# STM32H755ZIT7@M7 register map
File version: 1.0
Registers are 32-bit, access not given, reset 0x0 unless marked. A register's access mark holds for its fields unless they carry their own. Offsets are from the block's base; [hi:lo] are bit positions; {n}, {i} and the like mark numbered series; 'fields as' and 'values as' point back to an identical list.

## FDCAN_CCU
Base 0x4000A800
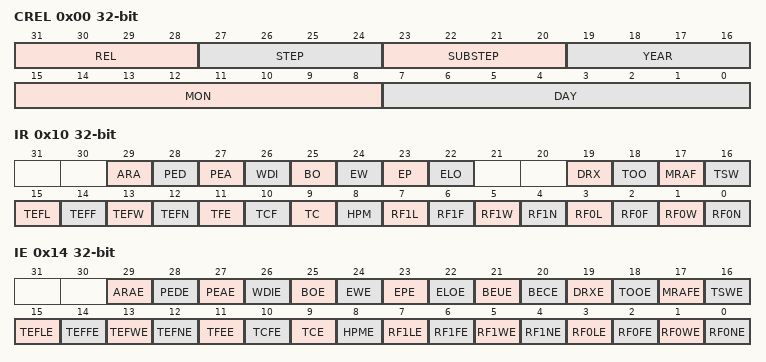
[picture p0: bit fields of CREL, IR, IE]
0x00 CREL
  [31:28] REL, [27:24] STEP, [23:20] SUBSTEP, [19:16] YEAR, [15:8] MON, [7:0] DAY
0x04 CCFG
0x08 CSTAT
0x0C CWD
0x10 IR
  [29] ARA, [28] PED, [27] PEA, [26] WDI, [25] BO, [24] EW, [23] EP, [22] ELO, [19] DRX, [18] TOO, [17] MRAF, [16] TSW, [15] TEFL, [14] TEFF, [13] TEFW, [12] TEFN, [11] TFE, [10] TCF, [9] TC, [8] HPM, [7] RF1L, [6] RF1F, [5] RF1W, [4] RF1N, [3] RF0L, [2] RF0F, [1] RF0W, [0] RF0N
0x14 IE
  [29] ARAE, [28] PEDE, [27] PEAE, [26] WDIE, [25] BOE, [24] EWE, [23] EPE, [22] ELOE, [21] BEUE, [20] BECE, [19] DRXE, [18] TOOE, [17] MRAFE, [16] TSWE, [15] TEFLE, [14] TEFFE, [13] TEFWE, [12] TEFNE, [11] TFEE, [10] TCFE, [9] TCE, [8] HPME, [7] RF1LE, [6] RF1FE, [5] RF1WE, [4] RF1NE, [3] RF0LE, [2] RF0FE, [1] RF0WE, [0] RF0NE

## SAI1
Base 0x40015800
Same registers: SAI2 0x40015C00, SAI3 0x40016000, SAI4 0x58005400
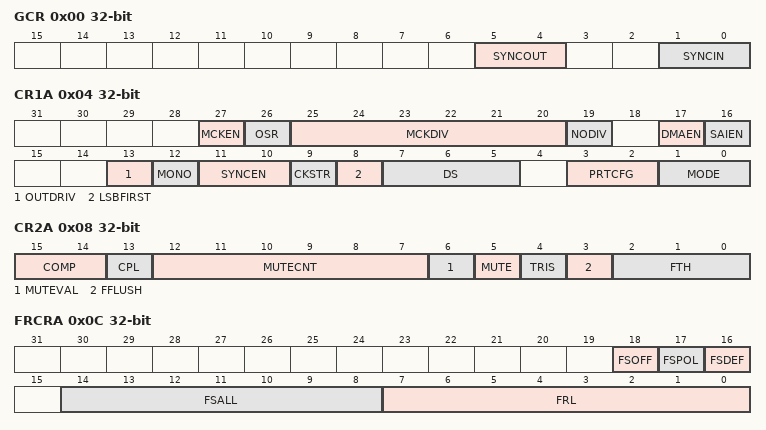
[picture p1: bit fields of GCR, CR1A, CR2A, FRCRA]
0x00 GCR
  [5:4] SYNCOUT, [1:0] SYNCIN
0x04 CR1A
  [27] MCKEN, [26] OSR, [25:20] MCKDIV, [19] NODIV, [17] DMAEN, [16] SAIEN, [13] OUTDRIV, [12] MONO, [11:10] SYNCEN, [9] CKSTR, [8] LSBFIRST, [7:5] DS, [3:2] PRTCFG, [1:0] MODE
0x08 CR2A
  [15:14] COMP, [13] CPL, [12:7] MUTECNT, [6] MUTEVAL, [5] MUTE, [4] TRIS, [3] FFLUSH, [2:0] FTH
0x0C FRCRA
  [18] FSOFF, [17] FSPOL, [16] FSDEF, [14:8] FSALL, [7:0] FRL
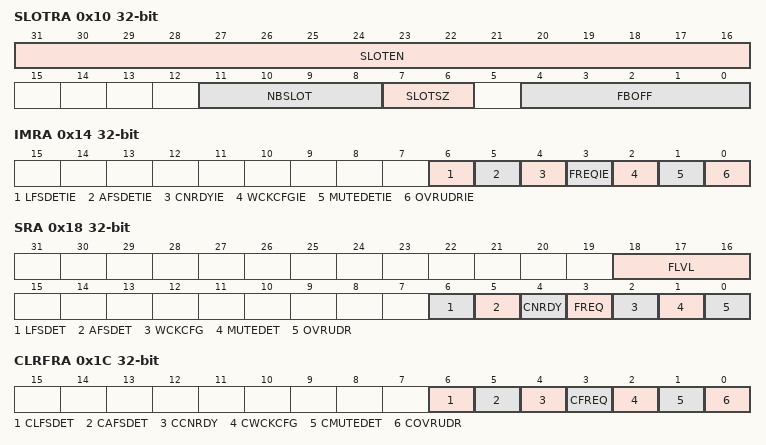
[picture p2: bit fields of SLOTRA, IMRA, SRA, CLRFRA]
0x10 SLOTRA
  [31:16] SLOTEN, [11:8] NBSLOT, [7:6] SLOTSZ, [4:0] FBOFF
0x14 IMRA
  [6] LFSDETIE, [5] AFSDETIE, [4] CNRDYIE, [3] FREQIE, [2] WCKCFGIE, [1] MUTEDETIE, [0] OVRUDRIE
0x18 SRA
  [18:16] FLVL, [6] LFSDET, [5] AFSDET, [4] CNRDY, [3] FREQ, [2] WCKCFG, [1] MUTEDET, [0] OVRUDR
0x1C CLRFRA
  [6] CLFSDET, [5] CAFSDET, [4] CCNRDY, [3] CFREQ, [2] CWCKCFG, [1] CMUTEDET, [0] COVRUDR
0x20 DRA
  [31:0] DATA
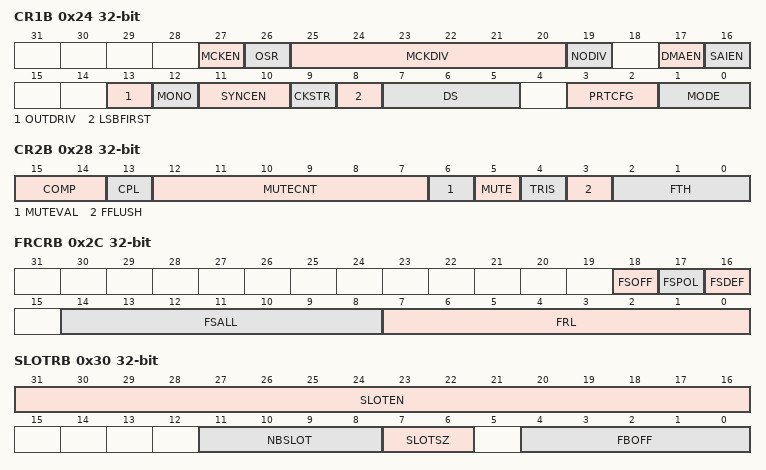
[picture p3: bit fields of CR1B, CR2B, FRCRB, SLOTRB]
0x24 CR1B
  fields as CR1A
0x28 CR2B
  fields as CR2A
0x2C FRCRB
  [18] FSOFF, [17] FSPOL, [16] FSDEF, [14:8] FSALL, [7:0] FRL
0x30 SLOTRB
  [31:16] SLOTEN, [11:8] NBSLOT, [7:6] SLOTSZ, [4:0] FBOFF
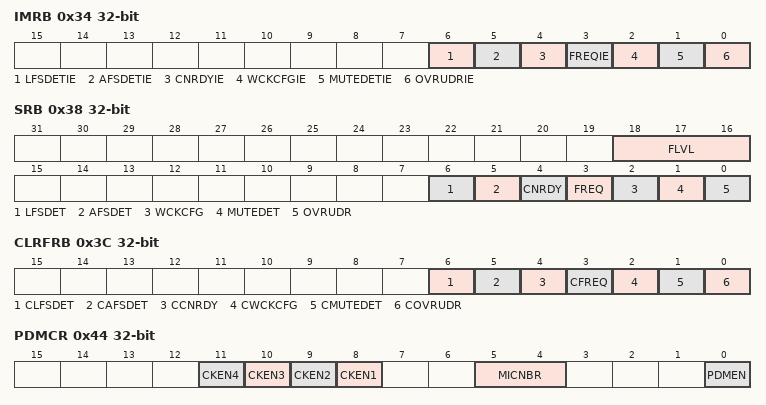
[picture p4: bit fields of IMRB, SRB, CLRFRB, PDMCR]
0x34 IMRB
  fields as IMRA
0x38 SRB
  fields as SRA
0x3C CLRFRB
  fields as CLRFRA
0x40 DRB
  [31:0] DATA
0x44 PDMCR
  [n+7] CKEN{n} (n=1..4), [5:4] MICNBR, [0] PDMEN
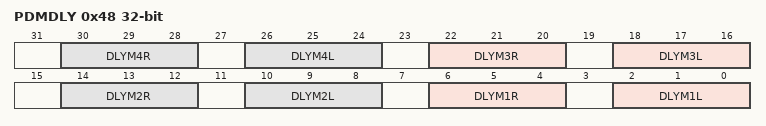
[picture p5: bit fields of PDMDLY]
0x48 PDMDLY
  [8n-2:8n-4] DLYM{n}R (n=1..4), [8n-6:8n-8] DLYM{n}L (n=1..4)

## DFSDM1
Base 0x40017000
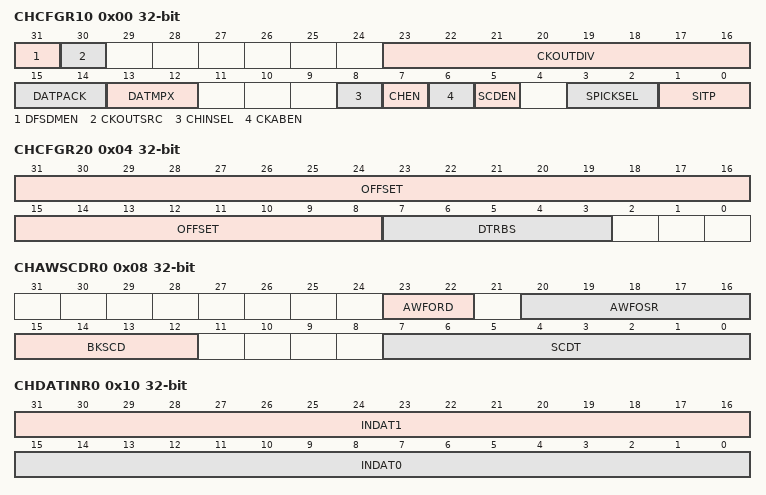
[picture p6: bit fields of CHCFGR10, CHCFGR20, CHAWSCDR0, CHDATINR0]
0x00 CHCFGR10
  [31] DFSDMEN, [30] CKOUTSRC, [23:16] CKOUTDIV, [15:14] DATPACK, [13:12] DATMPX, [8] CHINSEL, [7] CHEN, [6] CKABEN, [5] SCDEN, [3:2] SPICKSEL, [1:0] SITP
0x04 CHCFGR20
  [31:8] OFFSET, [7:3] DTRBS
0x08 CHAWSCDR0
  [23:22] AWFORD, [20:16] AWFOSR, [15:12] BKSCD, [7:0] SCDT
0x0C CHWDATAR0
0x10 CHDATINR0
  [31:16] INDAT1, [15:0] INDAT0
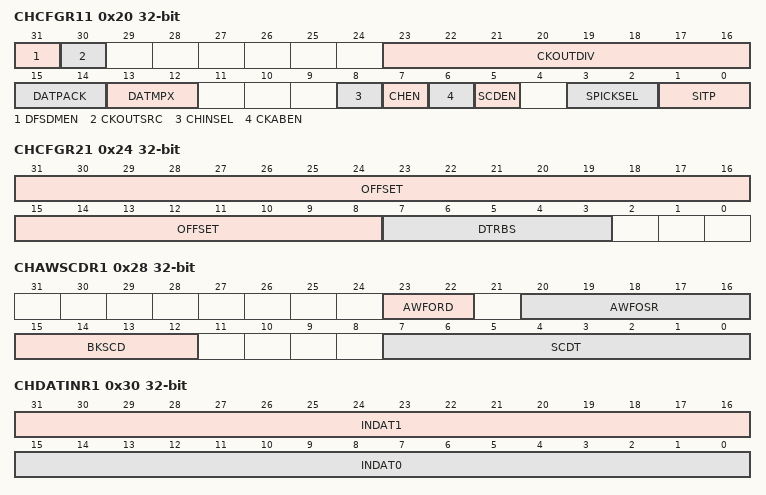
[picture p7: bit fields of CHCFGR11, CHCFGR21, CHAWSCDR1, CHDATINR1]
0x20 CHCFGR11
  fields as CHCFGR10
0x24 CHCFGR21
  [31:8] OFFSET, [7:3] DTRBS
0x28 CHAWSCDR1
  [23:22] AWFORD, [20:16] AWFOSR, [15:12] BKSCD, [7:0] SCDT
0x2C CHWDATAR1
0x30 CHDATINR1
  [31:16] INDAT1, [15:0] INDAT0
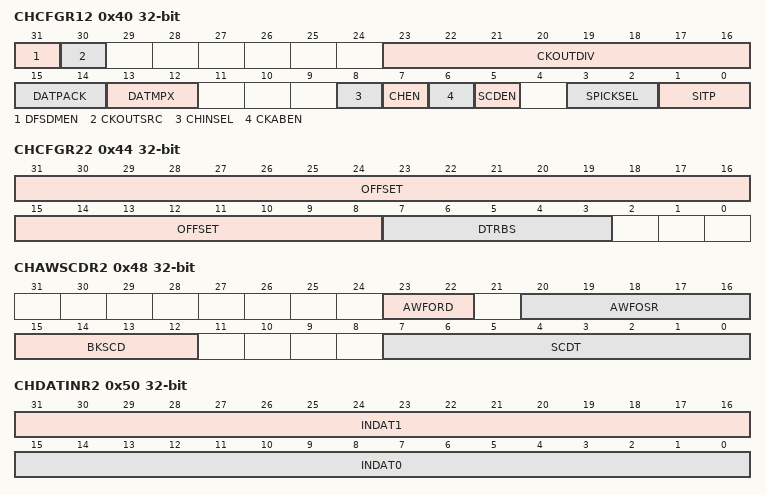
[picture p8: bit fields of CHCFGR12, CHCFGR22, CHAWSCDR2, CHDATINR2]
0x40 CHCFGR12
  fields as CHCFGR10
0x44 CHCFGR22
  [31:8] OFFSET, [7:3] DTRBS
0x48 CHAWSCDR2
  [23:22] AWFORD, [20:16] AWFOSR, [15:12] BKSCD, [7:0] SCDT
0x4C CHWDATAR2
0x50 CHDATINR2
  [31:16] INDAT1, [15:0] INDAT0
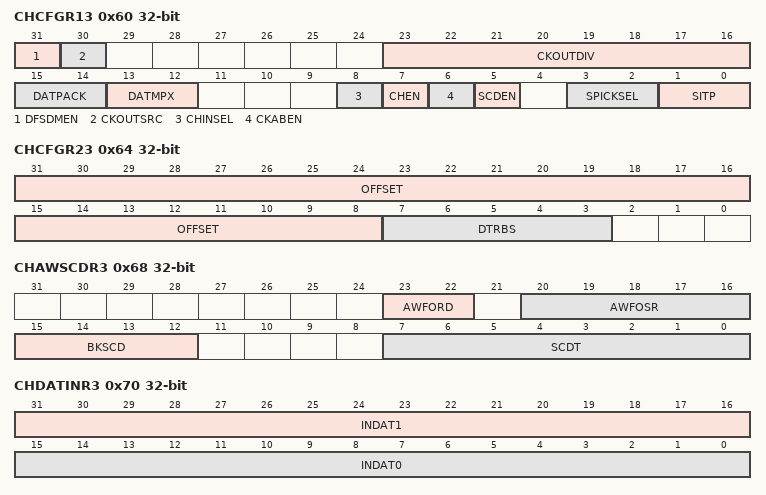
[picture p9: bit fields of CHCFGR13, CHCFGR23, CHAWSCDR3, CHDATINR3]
0x60 CHCFGR13
  fields as CHCFGR10
0x64 CHCFGR23
  [31:8] OFFSET, [7:3] DTRBS
0x68 CHAWSCDR3
  [23:22] AWFORD, [20:16] AWFOSR, [15:12] BKSCD, [7:0] SCDT
0x6C CHWDATAR3
0x70 CHDATINR3
  [31:16] INDAT1, [15:0] INDAT0
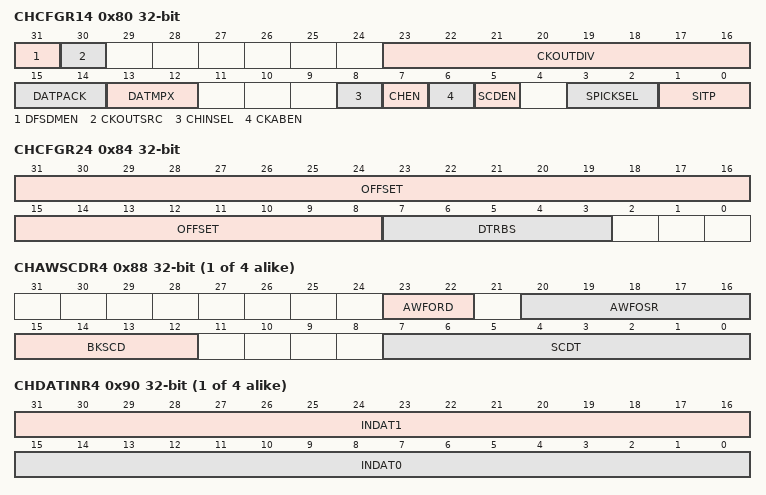
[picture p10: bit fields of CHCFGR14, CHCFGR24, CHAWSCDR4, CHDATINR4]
0x80 CHCFGR14
  fields as CHCFGR10
0x84 CHCFGR24
  [31:8] OFFSET, [7:3] DTRBS
{0x8+0x20*i} CHAWSCDR{i} (i=4..7)
  [23:22] AWFORD, [20:16] AWFOSR, [15:12] BKSCD, [7:0] SCDT
{0xC+0x20*i} CHWDATAR{i} (i=4..7)
{0x10+0x20*i} CHDATINR{i} (i=4..7)
  [31:16] INDAT1, [15:0] INDAT0
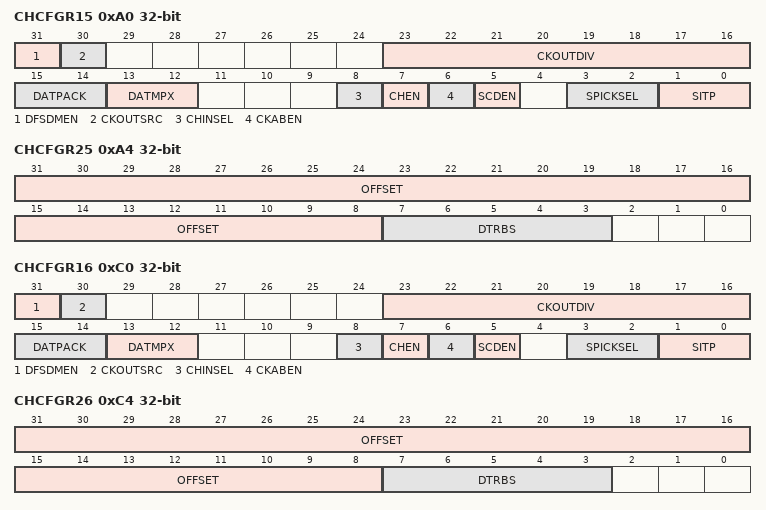
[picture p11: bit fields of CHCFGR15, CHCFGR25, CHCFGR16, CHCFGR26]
0xA0 CHCFGR15
  fields as CHCFGR10
0xA4 CHCFGR25
  [31:8] OFFSET, [7:3] DTRBS
0xC0 CHCFGR16
  fields as CHCFGR10
0xC4 CHCFGR26
  [31:8] OFFSET, [7:3] DTRBS
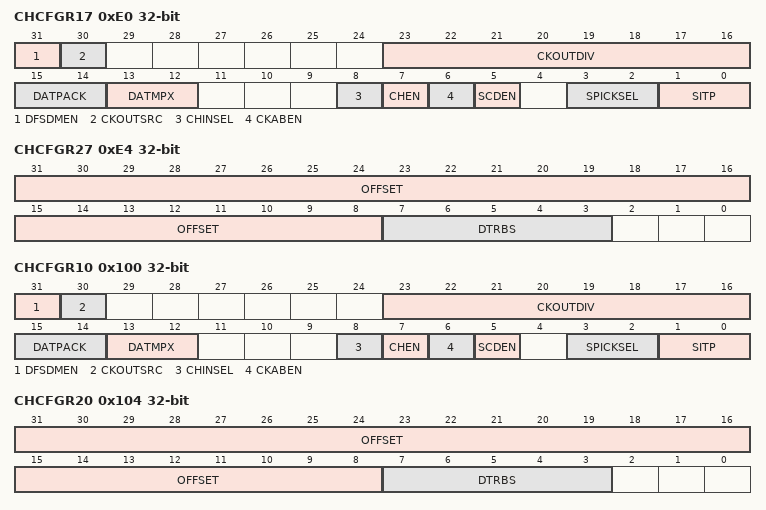
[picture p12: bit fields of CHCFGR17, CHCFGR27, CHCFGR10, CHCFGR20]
0xE0 CHCFGR17
  fields as CHCFGR10
0xE4 CHCFGR27
  [31:8] OFFSET, [7:3] DTRBS
0x100 CHCFGR10
  fields as CHCFGR10
0x104 CHCFGR20
  [31:8] OFFSET, [7:3] DTRBS
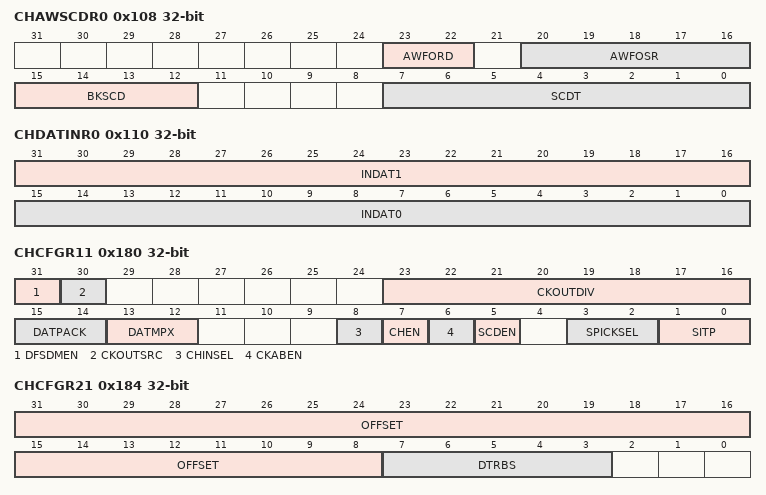
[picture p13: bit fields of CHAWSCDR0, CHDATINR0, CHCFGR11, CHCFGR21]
0x108 CHAWSCDR0
  [23:22] AWFORD, [20:16] AWFOSR, [15:12] BKSCD, [7:0] SCDT
0x10C CHWDATAR0
0x110 CHDATINR0
  [31:16] INDAT1, [15:0] INDAT0
0x180 CHCFGR11
  fields as CHCFGR10
0x184 CHCFGR21
  [31:8] OFFSET, [7:3] DTRBS
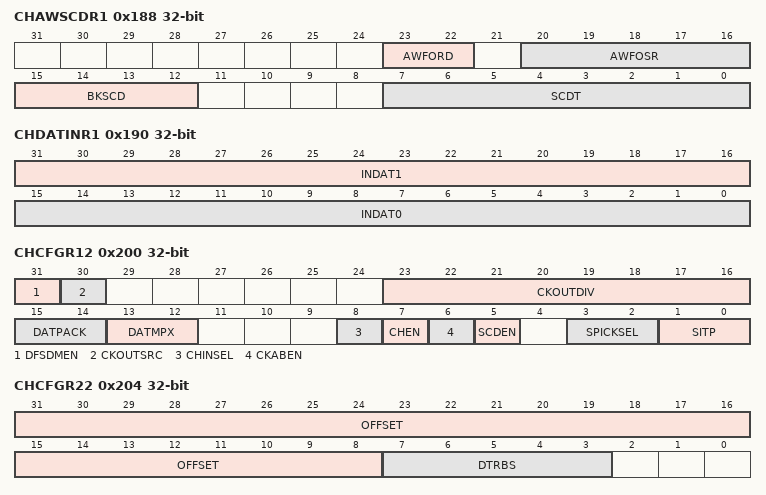
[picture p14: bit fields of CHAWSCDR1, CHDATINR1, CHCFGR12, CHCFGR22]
0x188 CHAWSCDR1
  [23:22] AWFORD, [20:16] AWFOSR, [15:12] BKSCD, [7:0] SCDT
0x18C CHWDATAR1
0x190 CHDATINR1
  [31:16] INDAT1, [15:0] INDAT0
0x200 CHCFGR12
  fields as CHCFGR10
0x204 CHCFGR22
  [31:8] OFFSET, [7:3] DTRBS
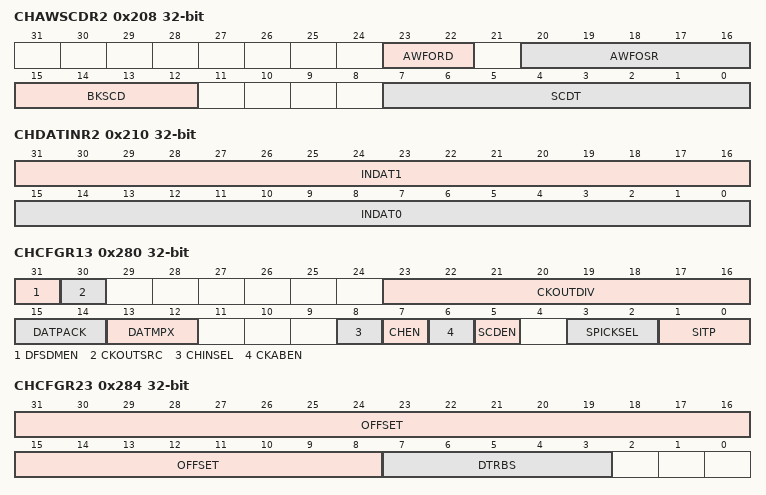
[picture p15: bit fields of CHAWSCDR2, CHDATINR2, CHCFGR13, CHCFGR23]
0x208 CHAWSCDR2
  [23:22] AWFORD, [20:16] AWFOSR, [15:12] BKSCD, [7:0] SCDT
0x20C CHWDATAR2
0x210 CHDATINR2
  [31:16] INDAT1, [15:0] INDAT0
0x280 CHCFGR13
  fields as CHCFGR10
0x284 CHCFGR23
  [31:8] OFFSET, [7:3] DTRBS
0x288 CHAWSCDR3
  [23:22] AWFORD, [20:16] AWFOSR, [15:12] BKSCD, [7:0] SCDT
0x28C CHWDATAR3
0x290 CHDATINR3
  [31:16] INDAT1, [15:0] INDAT0
